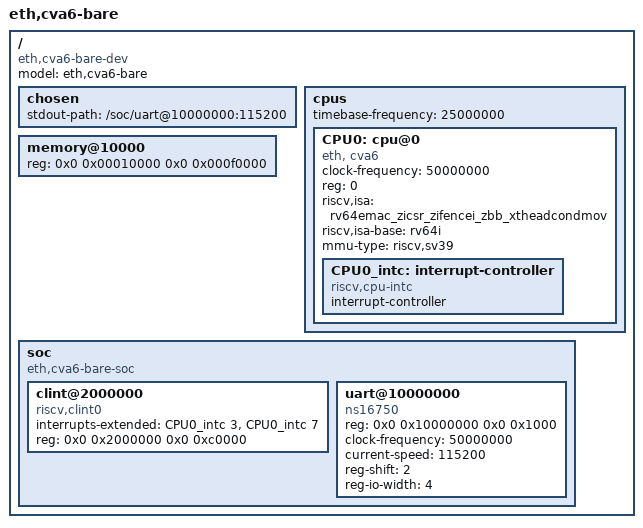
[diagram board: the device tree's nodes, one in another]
/dts-v1/;

/* Minimal in-aperture DTB for OpenSBI banner bring-up diagnosis.
 * Only the nodes early init strictly needs: root model, /chosen stdout,
 * one cpu (for the hart enumeration + isa), memory (in-aperture), and the
 * minimal /soc with clint + uart8250. Drops PLIC/timer/spi/eth/gpio/leds
 * to test whether a specific full-DTB node drives the early-init loop. */
/memreserve/ 0x00010000 0x000c0000;

/ {
  #address-cells = <2>;
  #size-cells = <2>;
  compatible = "eth,cva6-bare-dev";
  model = "eth,cva6-bare";
  chosen {
    stdout-path = "/soc/uart@10000000:115200";
  };
  cpus {
    #address-cells = <1>;
    #size-cells = <0>;
    timebase-frequency = <25000000>;
    CPU0: cpu@0 {
      clock-frequency = <50000000>;
      device_type = "cpu";
      reg = <0>;
      status = "okay";
      compatible = "eth, cva6", "riscv";
      riscv,isa = "rv64emac_zicsr_zifencei_zbb_xtheadcondmov";
      riscv,isa-base = "rv64i";
      mmu-type = "riscv,sv39";
      CPU0_intc: interrupt-controller {
        #interrupt-cells = <1>;
        interrupt-controller;
        compatible = "riscv,cpu-intc";
      };
    };
  };
  memory@10000 {
    device_type = "memory";
    reg = <0x0 0x00010000 0x0 0x000f0000>;
  };
  soc {
    #address-cells = <2>;
    #size-cells = <2>;
    compatible = "eth,cva6-bare-soc", "simple-bus";
    ranges;
    clint@2000000 {
      compatible = "riscv,clint0";
      interrupts-extended = <&CPU0_intc 3 &CPU0_intc 7>;
      reg = <0x0 0x2000000 0x0 0xc0000>;
    };
    uart@10000000 {
      compatible = "ns16750", "ns16550";
      reg = <0x0 0x10000000 0x0 0x1000>;
      clock-frequency = <50000000>;
      current-speed = <115200>;
      reg-shift = <2>;
      reg-io-width = <4>;
    };
  };
};
